# CTRL_MMR0_CTRL_MMR0_CLK_MMRS_09100000h register map
Vendor: Texas Instruments
Peripheral module from a debugger description file (folder am62L).
Registers are 32-bit, read-write, reset 0x0 unless marked. A register's access mark holds for its fields unless they carry their own. Offsets are as the file gives them; lines under a group give offsets from that group; [hi:lo] are bit positions; {n}, {i} and the like mark numbered series; 'fields as' and 'values as' point back to an identical list; <NAME> marks a mode.

## CTRL_MMR0_CLK_MMRS
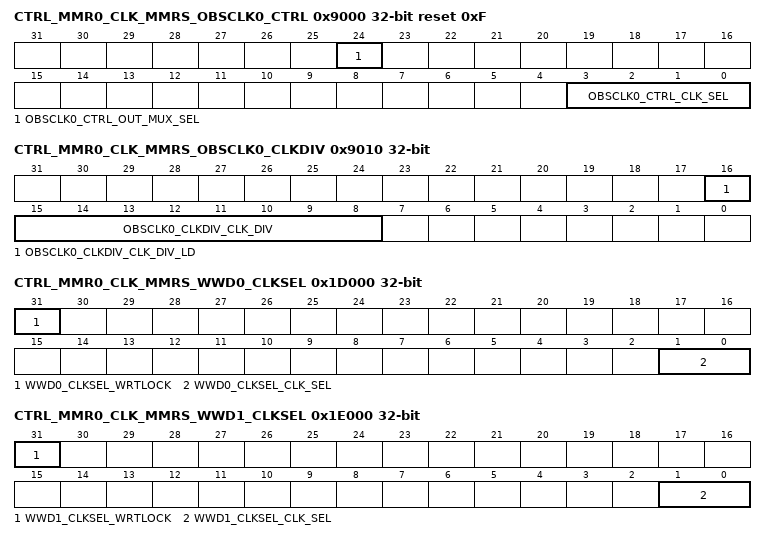
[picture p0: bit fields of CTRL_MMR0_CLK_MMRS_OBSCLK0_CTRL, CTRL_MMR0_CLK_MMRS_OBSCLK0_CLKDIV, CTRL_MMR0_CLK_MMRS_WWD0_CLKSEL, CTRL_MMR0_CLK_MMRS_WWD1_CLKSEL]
0x9000 CTRL_MMR0_CLK_MMRS_OBSCLK0_CTRL reset 0xF — This register controls which internal clock is made observable on the OBSCLK0 output pin
  [24] OBSCLK0_CTRL_OUT_MUX_SEL — OBSCLK0 pin output mux selection. HFOSC0_CLK is a direct output from the HFOSC0, CLK_DIV_OUT is the output of the OBSCLK0 Output Clock Divider. The input to this divider is selcted by the clk_sel field of this MMR.Field values (others are reserved):1'b0 - CLK_DIV_OUT1'b1 - HFOSC0_CLK (clk_sel must be OFF) Reset Source: mod_por_rst_n
  [3:0] OBSCLK0_CTRL_CLK_SEL — OBSCLK0 clock source selection - determines the clock at the input of the OBSCLK0 Output Clock Divider.Field values (others are reserved):4'b0000 - MAIN_PLL0_HSDIV0_CLKOUTundefined - undefinedundefined - undefined4'b0011 - MPUSS_CLK_DIV44'b0100 - DDRSS_CLK_DIV44'b0101 - CLK_12M_RC4'b0110 - HFOSC0_CLKOUT_32K4'b0111 - PLLCTRL_OBSCLK4'b1000 - HFOSC0_CLKOUT4'b1001 - CPSW0_CPTS_GENF04'b1010 - CPSW0_CPTS_GENF14'b1011 - MAIN_PLL17_HSDIV0_CLKOUT4'b1100 - CLK_32K_RC Reset Source: mod_por_rst_n
0x9010 CTRL_MMR0_CLK_MMRS_OBSCLK0_CLKDIV — This register controls the output divider value for the OBSCLK0 output pin
  [16] OBSCLK0_CLKDIV_CLK_DIV_LD — Load divisor value from clk_div field, when the bit is toggled from 0 to 1. Reset Source: mod_por_rst_n
  [15:8] OBSCLK0_CLKDIV_CLK_DIV — OBSCLK0 Output Clock Divider value. Sets divider to divide by clkdiv + 1. Divide by 1 to 256 are supported. After Writing to this field, the clk_div_ld field must be toggled. Reset Source: mod_por_rst_n
0xA000 CTRL_MMR0_CLK_MMRS_CLKOUT_CLKSEL — Selects clock source of CPSW CLKOUT pin
  [0] CLKOUT_CLKSEL_CLK_SEL — Selects CLKOUT clock sourceField values (others are reserved):1'b0 - MAIN_PLL0_HSDIV6_CLKOUT_DIV51'b1 - MAIN_PLL0_HSDIV6_CLKOUT_DIV10 Reset Source: mod_g_rst_n
0xB000 CTRL_MMR0_CLK_MMRS_EMMC0_CLKSEL — Selects the functional clock source for 8-bit eMMC0
  [0] EMMC0_CLKSEL_EMMCSD_REFCLK_SEL — Selects the functional clock for the MMC0 ModuleField values (others are reserved):1'b0 - MAIN_PLL0_HSDIV5_CLKOUT1'b1 - WKUP_PLL0_HSDIV9_CLKOUT Reset Source: mod_g_rst_n
0xC000 CTRL_MMR0_CLK_MMRS_EMMC1_CLKSEL reset 0x1 — Selects the functional clock source for 4-bit eMMC1
  [0] EMMC1_CLKSEL_EMMCSD_REFCLK_SEL — Selects the functional clock for the MMC1 ModuleField values (others are reserved):1'b0 - MAIN_PLL0_HSDIV5_CLKOUT1'b1 - WKUP_PLL0_HSDIV9_CLKOUT Reset Source: mod_g_rst_n
0xD000 CTRL_MMR0_CLK_MMRS_EMMC2_CLKSEL reset 0x1 — Selects the functional clock source for 4-bit eMMC2
  [0] EMMC2_CLKSEL_EMMCSD_REFCLK_SEL — Selects the functional clock for the MMC2 ModuleField values (others are reserved):1'b0 - MAIN_PLL0_HSDIV5_CLKOUT1'b1 - WKUP_PLL0_HSDIV9_CLKOUT Reset Source: mod_g_rst_n
0x11000 CTRL_MMR0_CLK_MMRS_OSPI0_CLKSEL — Selects the OSPI0 clock source
  [0] OSPI0_CLKSEL_CLK_SEL — OSPI0 reference clock selectionField values (others are reserved):1'b0 - MAIN_PLL0_HSDIV7_CLKOUT1'b1 - WKUP_PLL0_HSDIV4_CLKOUT Reset Source: mod_g_rst_n
0x14000 CTRL_MMR0_CLK_MMRS_GPMC_CLKSEL — Selects the bus and functional clock source for the GPMC module. This allows the GPMC to run asynchronously to the bus fabric in order to optimize parallel port performance.
  [0] GPMC_CLKSEL_CLK_SEL — Selects the GPMC clock source:Field values (others are reserved):1'b0 - MAIN_PLL0_HSDIV3_CLKOUT1'b1 - WKUP_PLL0_HSDIV3_CLKOUT Reset Source: mod_g_rst_n
{0x15000+0x1000*i} CTRL_MMR0_CLK_MMRS_TIMER{i}_CLKSEL (i=0..3) — Timer{i} functional clock selection control
  [3:0] TIMER{i}_CLKSEL_CLK_SEL — Timer functional clock input select mux control (Reserved values default to HFOSC0_CLK)Field values (others are reserved):4'b0000 - HFOSC0_CLKOUT4'b0001 - DEVICE_CLKOUT_32K4'b0010 - MAIN_PLL0_HSDIV6_CLKOUT4'b0011 - CLK_12M_RC4'b0100 - WKUP_EXT_REFCLK0 (Pin)4'b0101 - EXT_REFCLK1 (Pin)undefined - undefined4'b0111 - CP_GEMAC_CPTS0_RFT_CLK (Pin)4'b1000 - WKUP_PLL0_HSDIV1_CLKOUT4'b1001 - WKUP_PLL0_HSDIV7_CLKOUT4'b1010 - CPSW0_CPTS_GENF04'b1011 - CPSW0_CPTS_GENF1 Reset Source: sys_por_rst_n
0x1D000 CTRL_MMR0_CLK_MMRS_WWD0_CLKSEL — Windowed Watchdog WWD0 functional clock selection control
  [31] WWD0_CLKSEL_WRTLOCK — When set, locks WWD0_CLKSEL from further writes until the next module reset.Field values (others are reserved):1'b0 - UNLOCKED1'b1 - LOCKED Reset Source: mod_g_rst_n
  [1:0] WWD0_CLKSEL_CLK_SEL — Windowed watchdog timer functional clock input select mux controlField values (others are reserved):2'b00 - HFOSC0_CLKOUT2'b01 - DEVICE_CLKOUT_32K2'b10 - CLK_12M_RC2'b11 - CLK_32K Reset Source: mod_g_rst_n
0x1E000 CTRL_MMR0_CLK_MMRS_WWD1_CLKSEL — Windowed Watchdog WWD1 functional clock selection control
  [31] WWD1_CLKSEL_WRTLOCK — When set, locks WWD1_CLKSEL from further writes until the next module reset.Field values (others are reserved):1'b0 - UNLOCKED1'b1 - LOCKED Reset Source: mod_g_rst_n
  [1:0] WWD1_CLKSEL_CLK_SEL — Windowed watchdog timer functional clock input select mux controlField values (others are reserved):2'b00 - HFOSC0_CLKOUT2'b01 - DEVICE_CLKOUT_32K2'b10 - CLK_12M_RC2'b11 - CLK_32K Reset Source: mod_g_rst_n
{0x26000+0x1000*i} CTRL_MMR0_CLK_MMRS_SPI{i}_CLKSEL (i=0..3) — SPI{i} clock control
  [16] SPI{i}_CLKSEL_MSTR_LB_CLKSEL — Controller mode receive capture clock loopback selection. (When SPI is in device mode, this field is ignored and EXTERNAL_LOOPBACK is forced)Field values (others are reserved):1'b0 - INTERNAL_LOOPBACK1'b1 - EXTERNAL_LOOPBACK Reset Source: mod_g_rst_n
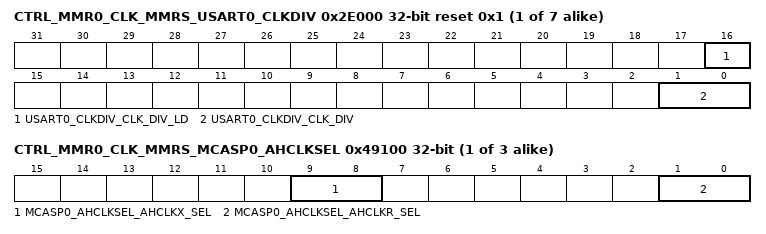
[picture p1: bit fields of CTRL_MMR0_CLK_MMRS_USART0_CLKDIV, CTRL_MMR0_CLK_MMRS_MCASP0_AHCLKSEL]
{0x2E000+0x1000*i} CTRL_MMR0_CLK_MMRS_USART{i}_CLKDIV reset 0x1 (i=0..6) — Selects the clock divider of the USART{i} functional clock
  [16] USART{i}_CLKDIV_CLK_DIV_LD — Load the output divider valueWriting 1 to this bit will generate a load pulse to load the USART{i} clock programmable divider value. This bit can be cleared but must not be set in the same write cycle in which the clk_div value is changed. Field values (others are reserved):1'b0 - READY1'b1 - LOAD Reset Source: mod_g_rst_n
  [1:0] USART{i}_CLKDIV_CLK_DIV — Selects the clock divider value. Supports divide values of 1 to 4 Default is /4. To load the new divider value the clk_div_ld bit must be cleared and then set to 1.Field values (others are reserved):2'b00 - DIV12'b01 - DIV22'b10 - DIV32'b11 - DIV4 Reset Source: mod_g_rst_n
0x3E000 CTRL_MMR0_CLK_MMRS_CPSW0_CLKSEL reset 0x7 — Selects the CPSW0 (Ethernet Switch) clock sources
  [2:0] CPSW0_CLKSEL_CPTS_CLKSEL — Selects the clock source for the CPSW Ethernet switch Common Platform Time Stamp moduleField values (others are reserved):3'b000 - WKUP_PLL0_HSDIV7_CLKOUT3'b001 - MAIN_PLL0_HSDIV6_CLKOUT3'b010 - CP_GEMAC_CPTS0_RFT_CLK (Pin)3'b011 - DEVICE_CLKOUT_32K3'b100 - WKUP_EXT_REFCLK0 (Pin)3'b101 - EXT_REFCLK1 (Pin)3'b110 - PER_SYSCLK03'b111 - MAIN_SYSCLK0 Reset Source: mod_por_rst_n
{0x40000+0x1000*i} CTRL_MMR0_CLK_MMRS_MCAN{i}_CLKSEL (i=0..2) — Controls the functional clock source MCAN{i}
  [1:0] MCAN{i}_CLKSEL_CLK_SEL — MAIN MCAN_CLK selectionField values (others are reserved):2'b00 - MAIN_PLL0_HSDIV4_CLKOUT2'b01 - WKUP_EXT_REFCLK0 (Pin)2'b10 - EXT_REFCLK1 (Pin)2'b11 - HFOSC0_CLKOUT Reset Source: sys_por_rst_n
0x48000 CTRL_MMR0_CLK_MMRS_AUDIO_REFCLK0_CLKSEL reset 0x7 — Selects the clock source for AUDIO_EXT_REFCLK0
  [2:0] AUDIO_REFCLK0_CLKSEL_CLK_SEL — Selects the source of AUDIO_REFCLK0. When a McASP is selected, the McASP controls the pin direction. When a PLL source is selected, the pin direction is output.Field values (others are reserved):3'b000 - MCASP0_AHCLKR3'b001 - MCASP1_AHCLKR3'b010 - MCASP2_AHCLKR3'b011 - MCASP0_AHCLKX3'b100 - MCASP1_AHCLKX3'b101 - MCASP2_AHCLKX3'b110 - MAIN_PLL0_HSDIV8_CLKOUT3'b111 - WKUP_PLL0_HSDIV1_CLKOUT Reset Source: mod_g_rst_n
0x48010 CTRL_MMR0_CLK_MMRS_AUDIO_REFCLK1_CLKSEL reset 0x7 — Selects the clock source for AUDIO_EXT_REFCLK0
  [2:0] AUDIO_REFCLK1_CLKSEL_CLK_SEL — Selects the source of AUDIO_REFCLK1. When a McASP is selected, the McASP controls the pin direction. When a PLL source is selected, the pin direction is output.Field values (others are reserved):3'b000 - MCASP0_AHCLKR3'b001 - MCASP1_AHCLKR3'b010 - MCASP2_AHCLKR3'b011 - MCASP0_AHCLKX3'b100 - MCASP1_AHCLKX3'b101 - MCASP2_AHCLKX3'b110 - MAIN_PLL0_HSDIV8_CLKOUT3'b111 - WKUP_PLL0_HSDIV1_CLKOUT Reset Source: mod_g_rst_n
{0x49000+0x1000*i} CTRL_MMR0_CLK_MMRS_MCASP{i}_CLKSEL (i=0..2) — Selects the functional clock source for McASP{i}
  [0] MCASP{i}_CLKSEL_AUXCLK_SEL — Selects the AUXCLK input source for McASP0Field values (others are reserved):1'b0 - MAIN_PLL0_HSDIV8_CLKOUT1'b1 - WKUP_PLL0_HSDIV1_CLKOUT Reset Source: mod_g_rst_n
{0x49100+0x1000*i} CTRL_MMR0_CLK_MMRS_MCASP{i}_AHCLKSEL (i=0..2) — Selects the AHCLKX and AHCLKR clock source for McASP{i}
  [9:8] MCASP{i}_AHCLKSEL_AHCLKX_SEL — Selects the AHCLKX input source for McASP{i}Field values (others are reserved):2'b00 - EXT_REFCLK1 (Pin)2'b01 - HFOSC0_CLKOUT2'b10 - AUDIO_EXT_REFCLK0 (Pin)2'b11 - AUDIO_EXT_REFCLK1 (Pin) Reset Source: mod_g_rst_n
  [1:0] MCASP{i}_AHCLKSEL_AHCLKR_SEL — Selects the AHCLKR input source for McASP{i}Field values (others are reserved):2'b00 - EXT_REFCLK1 (Pin)2'b01 - HFOSC0_CLKOUT2'b10 - AUDIO_EXT_REFCLK0 (Pin)2'b11 - AUDIO_EXT_REFCLK1 (Pin) Reset Source: mod_g_rst_n
0x5B000 CTRL_MMR0_CLK_MMRS_DSS0_DISPC0_CLKSEL — Selects the clock source for DPI of Display Controller 0 of Display Subsystem 0
  [0] DSS0_DISPC0_CLKSEL_DPI0_PCLK — DPI pixel Clock Source - DSS0_DISPC0_VP0Field values (others are reserved):1'b0 - MAIN_PLL16_HSDIV0_CLKOUT1'b1 - VOUT0_EXTPCLKIN Reset Source: mod_por_rst_n
0x63000 CTRL_MMR0_CLK_MMRS_DPHY0_CLKSEL — Selects the clock source for the DSI0 transmit PHY
  [0] DPHY0_CLKSEL_REF_CLK_SEL — DPHY reference clock sourceField values (others are reserved):1'b0 - HFOSC0_CLKOUT_SERDES1'b1 - MAIN_PLL0_HSDIV8_CLKOUT Reset Source: sys_por_rst_n
0x69000 CTRL_MMR0_CLK_MMRS_ADC0_CLKSEL — Controls the functional clock source for the ADC0
  [1:0] ADC0_CLKSEL_CLK_SEL — Selects the sampling clock source for ADC0Field values (others are reserved):2'b00 - HFOSC0_CLKOUT2'b01 - PER_SYSCLK0_DIV122'b10 - WKUP_PLL0_HSDIV8_CLKOUT2'b11 - EXT_REFCLK1 (Pin) Reset Source: mod_g_rst_n
